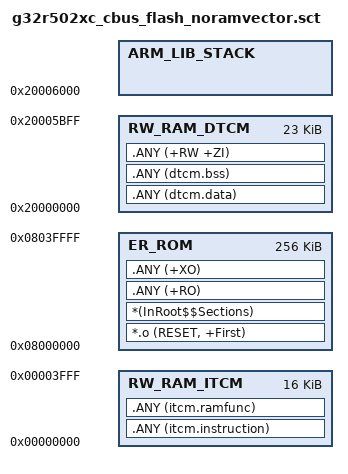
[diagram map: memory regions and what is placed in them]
#! armclang -E --target=arm-arm-none-eabi -mcpu=cortex-m52 -xc
;---------------------------------------------------------------------------
; FILE:    g32r502xc_cbus_flash_noramvector.sct
; TITLE:   MDK scatter for G32R502 library/benchmark (CBUS Flash, no RAM vector)
; VERSION: 1.0.0
; DATE:    2026-08-10
;---------------------------------------------------------------------------
; command above MUST be in first line (no comment above!)

/*
;-------- <<< Use Configuration Wizard in Context Menu >>> -------------------
*/

/*--------------------- ITCM / DTCM RAM Configuration --------------------------
; <h> ITCM / DTCM RAM Configuration
;   <o0> ITCM Base Address <0x0-0xFFFFFFFF:8>
;   <o1> ITCM Size (in Bytes) <0x0-0xFFFFFFFF:8>
;   <o2> DTCM Base Address <0x0-0xFFFFFFFF:8>
;   <o3> DTCM Size (in Bytes) <0x0-0xFFFFFFFF:8>
; </h>
 *----------------------------------------------------------------------------*/
#define __ITCM_BASE              0x00000000
#define __ITCM_SIZE              0x00004000
#define __DTCM_BASE              0x20000000
#define __DTCM_SIZE              0x00006000

/*--------------------- CBUS Flash Configuration -------------------------------
; <h> CBUS Flash Configuration
;   <o0> CBUS Flash Base Address <0x0-0xFFFFFFFF:8>
;   <o1> CBUS Flash Size (in Bytes) <0x0-0xFFFFFFFF:8>
;   <i> G32R502 has no ITCM Flash interface.
; </h>
 *----------------------------------------------------------------------------*/
#define __CBUS_FLASH_BASE        0x08000000
#define __CBUS_FLASH_SIZE        0x00040000

#define __ROM_BASE               __CBUS_FLASH_BASE
#define __ROM_SIZE               __CBUS_FLASH_SIZE

/*--------------------- Stack / Heap Configuration ---------------------------
; <h> Stack / Heap Configuration
;   <o0> Stack Size (in Bytes) <0x0-0xFFFFFFFF:8>
;   <o1> Heap Size (in Bytes) <0x0-0xFFFFFFFF:8>
;   <o2> Stack Top Location
;      <0=> DTCM (Default)
;      <1=> ITCM
;   <i> Boot Status Snapshot (if enabled) stays at DTCM physical top.
; </h>
 *----------------------------------------------------------------------------*/
#define __STACK_SIZE                  0x00000400
#define __HEAP_SIZE                   0x00000000
#define __STACK_TOP_LOCATION          0
/*--------------------- Boot Status Snapshot Configuration -------------------
; <h> Boot Status Snapshot Configuration
;   <o> Reserve Boot Status Snapshot
;       <0=> Disabled
;       <1=> Reserve last 0x20 bytes of DTCM for Boot status snapshot
; </h>
 *----------------------------------------------------------------------------*/
#define __BOOT_STATUS_SNAPSHOT_ENABLE       0

#if __BOOT_STATUS_SNAPSHOT_ENABLE == 0
    #define __BOOT_STATUS_SNAPSHOT_SIZE     0x00000000
#elif __BOOT_STATUS_SNAPSHOT_ENABLE == 1
    #define __BOOT_STATUS_SNAPSHOT_SIZE     0x00000020
#else
    #error "Unsupported BOOT_STATUS_SNAPSHOT_ENABLE value"
#endif

/*--------------------- Generic RW/ZI Bank Configuration ---------------------
; <h> Generic RW/ZI Placement
;   <o> Generic +RW/+ZI Bank
;      <0=> DTCM only (Default)
;      <1=> ITCM only
;      <2=> DTCM first, spill to ITCM
;   <i> dtcm.data/dtcm.bss always in DTCM; itcm.instruction/itcm.ramfunc in ITCM.
;   <i> Stack/heap and .bss.ram.intvec placement are not affected.
; </h>
 *----------------------------------------------------------------------------*/
#define __RWZI_BANK  0

/*----------------------------------------------------------------------------
  Fixed layout: no RAM vector window; full DTCM for generic RW / stack
 *----------------------------------------------------------------------------*/
#define __DTCM_RW_BASE   __DTCM_BASE
#define __ITCM_RW_BASE   __ITCM_BASE
#define __ITCM_RW_SIZE_RAW   __ITCM_SIZE

#define __DTCM_TOP              (__DTCM_BASE + __DTCM_SIZE)
#define __ITCM_TOP              (__ITCM_BASE + __ITCM_SIZE)

#if __STACK_TOP_LOCATION == 0
    #define __DTCM_STACK_TAX    (__STACK_SIZE + __HEAP_SIZE)
    #define __ITCM_STACK_TAX    0
    #define __STACK_TOP         (__DTCM_TOP - __BOOT_STATUS_SNAPSHOT_SIZE)
#elif __STACK_TOP_LOCATION == 1
    #define __DTCM_STACK_TAX    0
    #define __ITCM_STACK_TAX    (__STACK_SIZE + __HEAP_SIZE)
    #define __STACK_TOP         __ITCM_TOP
#else
    #error "Invalid __STACK_TOP_LOCATION (G32R502: 0=DTCM, 1=ITCM)"
#endif

#define __ITCM_RW_SIZE   (__ITCM_RW_SIZE_RAW - __ITCM_STACK_TAX)
#define __DTCM_RW_SIZE   (__DTCM_SIZE - __DTCM_STACK_TAX - __BOOT_STATUS_SNAPSHOT_SIZE)
#define __HEAP_BASE             (AlignExpr((__STACK_TOP - __STACK_SIZE - __HEAP_SIZE), 8))

LR_ROM __ROM_BASE __ROM_SIZE {                     ; load region (code/const)
  ER_ROM __ROM_BASE __ROM_SIZE {                   ; exec = load
   *.o (RESET, +First)
   *(InRoot$$Sections)
   .ANY (+RO)
   .ANY (+XO)
  }

#if __RWZI_BANK == 0
  RW_RAM_ITCM __ITCM_RW_BASE __ITCM_RW_SIZE {
    .ANY (itcm.instruction)
    .ANY (itcm.ramfunc)
  }
  RW_RAM_DTCM __DTCM_RW_BASE __DTCM_RW_SIZE {
    .ANY (dtcm.data)
    .ANY (dtcm.bss)
    .ANY (+RW +ZI)
  }
#elif __RWZI_BANK == 1
  RW_RAM_ITCM __ITCM_RW_BASE __ITCM_RW_SIZE {
    .ANY (itcm.instruction)
    .ANY (itcm.ramfunc)
    .ANY (+RW +ZI)
  }
  RW_RAM_DTCM __DTCM_RW_BASE __DTCM_RW_SIZE {
    .ANY (dtcm.data)
    .ANY (dtcm.bss)
  }
#elif __RWZI_BANK == 2
  RW_RAM_DTCM __DTCM_RW_BASE __DTCM_RW_SIZE {
    .ANY (dtcm.data)
    .ANY (dtcm.bss)
    .ANY (+RW +ZI)
  }
  RW_RAM_ITCM __ITCM_RW_BASE __ITCM_RW_SIZE {
    .ANY (itcm.instruction)
    .ANY (itcm.ramfunc)
    .ANY (+RW +ZI)
  }
#else
  #error "Unsupported __RWZI_BANK value"
#endif

#if __HEAP_SIZE > 0
  ARM_LIB_HEAP __HEAP_BASE EMPTY __HEAP_SIZE {
  }
#endif

  ARM_LIB_STACK __STACK_TOP EMPTY - __STACK_SIZE {
  }

#if __BOOT_STATUS_SNAPSHOT_SIZE > 0
  BOOT_STATUS_SNAPSHOT (__DTCM_TOP - __BOOT_STATUS_SNAPSHOT_SIZE) EMPTY __BOOT_STATUS_SNAPSHOT_SIZE {
  }
#endif
}
